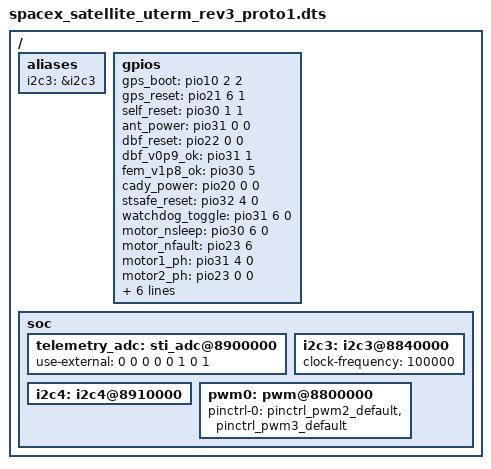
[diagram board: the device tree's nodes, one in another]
/*
 * Copyright (C) 2018 STMicroelectronics (R&D) Limited.
 * Author: Nicolas Toromanoff <nicolas.toromanoff@st.com>
 *
 * This program is free software; you can redistribute it and/or modify
 * it under the terms of the GNU General Public License version 2 as
 * published by the Free Software Foundation.
 */

/dts-v1/;
#include "spacex_satellite_uterm_cut4.dtsi"
#include "spacex_satellite_uterm_production.dtsi"
#include "spacex_satellite_uterm_imu_spi2.dtsi"

/ {
	aliases {
		i2c3 = &i2c3;
	};

	gpios {
		/*
		 * GPS.
		 */
		gps_boot  = <&pio10 2 2>; /* 2=inverted */
		gps_reset = <&pio21 6 1>; /* 0=reset, 1=run */

		/*
		 * Reset.
		 */
		self_reset = <&pio30 1 1>;   /* 0=reset */

		/*
		 * Antenna (DBFs + FEMs).
		 */
		ant_power = <&pio31 0 0>; /* 1=power 0.95/1.0/1.8V */

		/*
		 * Shiraz (digital beamformers).
		 */
		dbf_reset   = <&pio22 0 0>;
		dbf_v0p9_ok = <&pio31 1>;

		/*
		 * Pulsar (Front-End Modules).
		 */
		fem_v1p8_ok = <&pio30 5>;

		/*
		 * Cady (clockgen).
		 */
		cady_power = <&pio20 0 0>;

		/*
		 * STSAFE reset, active low.
		 */
		stsafe_reset = <&pio32 4 0>;

		/*
		 * Watchdog toggle. Must be toggled at least once in 144.
		 * seconds. Must stop toggling if self_reset is low.
		 */
		watchdog_toggle = <&pio31 6 0>;

		/*
		 * Motors reversed from schematic (1 -> 2).
		 */
		motor_nsleep = <&pio30 6 0>;
		motor_nfault = <&pio23 6>;
		motor1_ph    = <&pio31 4 0>;
		motor2_ph    = <&pio23 0 0>;

		/*
		 * AVS
		 */
		avs_b0  = <&pio10 4 0>;
		avs_b1  = <&pio0 3 0>;
		avs_b2  = <&pio0 0 0>;
		avs_b3  = <&pio0 4 0>;
		avs_b4  = <&pio0 1 0>;
		avs_nen = <&pio10 3 1>; /* Disabled by default */
	};

	soc {
		/*
		 * ADC temp sensors, voltage, and current monitors.
		 */
		telemetry_adc: sti_adc@8900000 {
			use-external = <0 0 0 0 0 1 0 1>;
		};

		/*
		 * I2C3 for controlling the MP8892 PMIC for AVS.
		 */
		i2c3: i2c3@8840000 {
			clock-frequency = <100000>;
			status = "okay";
		};

		/*
		 * I2C4 (SCL:PIO23[3],SDA:PIO23[4]) for talking to STSAFE IC.
		 */
		i2c4: i2c4@8910000 {
			status = "okay";
		};

		/*
		 * Remove AVS since pin doesn't exist for V3.
		 */
		pwm0: pwm@8800000 {
			pinctrl-0 = <&pinctrl_pwm2_default
				&pinctrl_pwm3_default>;
		};
	};
};
